VERSION "1.0"

NS_ :

BS_:

BU_: GENSET

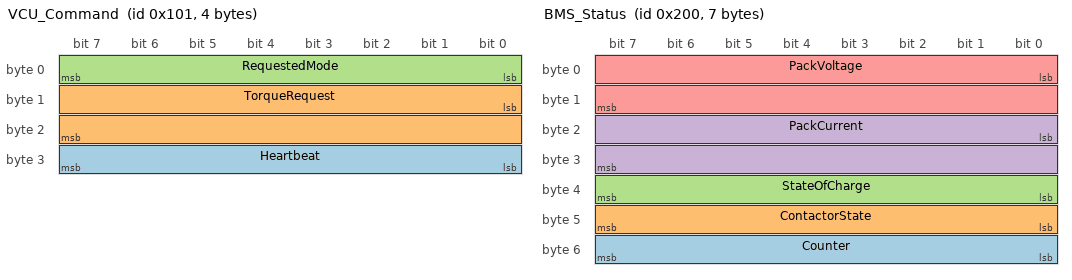
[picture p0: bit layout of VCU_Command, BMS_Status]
BO_ 257 VCU_Command: 4 VCU
 SG_ Heartbeat : 24|8@1+ (1,0) [0|255] ""  BMS,DCDC
 SG_ TorqueRequest : 8|16@1- (0.1,0) [-1000|1000] "Nm"  BMS,DCDC
 SG_ RequestedMode : 0|8@1+ (1,0) [0|3] ""  BMS,DCDC

BO_ 512 BMS_Status: 7 BMS
 SG_ Counter : 48|8@1+ (1,0) [0|255] ""  VCU,DCDC
 SG_ ContactorState : 40|8@1+ (1,0) [0|3] ""  VCU,DCDC
 SG_ StateOfCharge : 32|8@1+ (0.5,0) [0|100] "%"  VCU,DCDC
 SG_ PackCurrent : 16|16@1- (0.1,0) [-1000|1000] "A"  VCU,DCDC
 SG_ PackVoltage : 0|16@1+ (0.1,0) [0|1000] "V"  VCU,DCDC

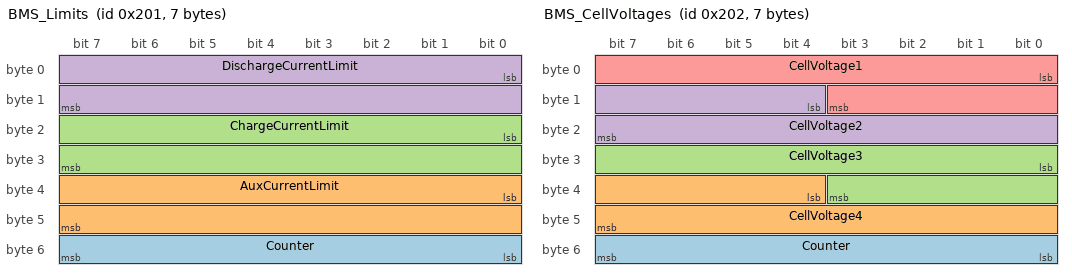
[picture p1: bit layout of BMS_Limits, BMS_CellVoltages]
BO_ 513 BMS_Limits: 7 BMS
 SG_ Counter : 48|8@1+ (1,0) [0|255] ""  VCU,DCDC
 SG_ AuxCurrentLimit : 32|16@1+ (0.01,0) [0|655.35] "A"  VCU,DCDC
 SG_ ChargeCurrentLimit : 16|16@1+ (0.01,0) [0|655.35] "A"  VCU,DCDC
 SG_ DischargeCurrentLimit : 0|16@1+ (0.01,0) [0|655.35] "A"  VCU,DCDC

BO_ 514 BMS_CellVoltages: 7 BMS
 SG_ Counter : 48|8@1+ (1,0) [0|255] ""  VCU
 SG_ CellVoltage4 : 36|12@1+ (0.001,2) [2|6.095] "V"  VCU
 SG_ CellVoltage3 : 24|12@1+ (0.001,2) [2|6.095] "V"  VCU
 SG_ CellVoltage2 : 12|12@1+ (0.001,2) [2|6.095] "V"  VCU
 SG_ CellVoltage1 : 0|12@1+ (0.001,2) [2|6.095] "V"  VCU

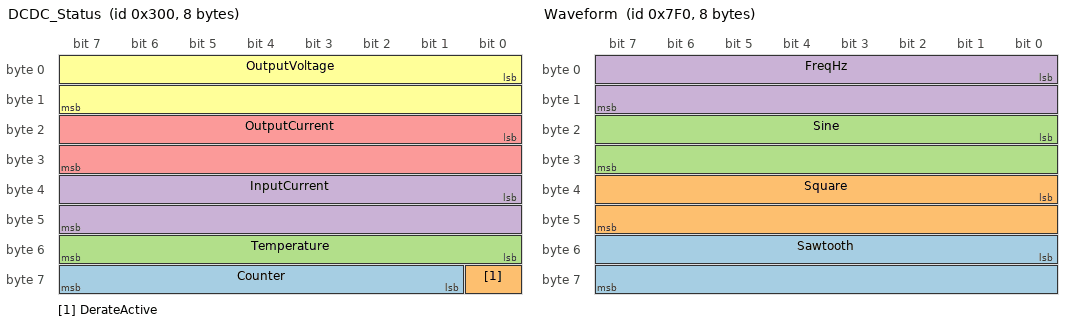
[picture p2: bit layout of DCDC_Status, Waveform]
BO_ 768 DCDC_Status: 8 DCDC
 SG_ Counter : 57|7@1+ (1,0) [0|127] ""  VCU,BMS
 SG_ DerateActive : 56|1@1+ (1,0) [0|1] ""  VCU,BMS
 SG_ Temperature : 48|8@1+ (1,-40) [-40|215] "degC"  VCU,BMS
 SG_ InputCurrent : 32|16@1+ (0.01,0) [0|655.35] "A"  VCU,BMS
 SG_ OutputCurrent : 16|16@1+ (0.1,0) [0|6553.5] "A"  VCU,BMS
 SG_ OutputVoltage : 0|16@1+ (0.01,0) [0|655.35] "V"  VCU,BMS

BO_ 2032 Waveform: 8 SIG
 SG_ Sawtooth : 48|16@1- (0.001,0) [-1|1] ""  VCU
 SG_ Square : 32|16@1- (0.001,0) [-1|1] ""  VCU
 SG_ Sine : 16|16@1- (0.001,0) [-1|1] ""  VCU
 SG_ FreqHz : 0|16@1+ (0.01,0) [0|655.35] "Hz"  VCU

BO_ 2364540032 EEC1: 8 GENSET
 SG_ EngineSpeed : 24|16@1+ (0.125,0) [0|8031.875] "rpm" Vector__XXX
 SG_ ActualEnginePercentTorque : 16|8@1+ (1,-125) [-125|125] "%" Vector__XXX

BO_ 2566844032 ET1: 8 GENSET
 SG_ EngineCoolantTemp : 0|8@1+ (1,-40) [-40|210] "degC" Vector__XXX

BO_ 2566838912 SOFT: 48 GENSET
 SG_ SoftwareIdByte47 : 376|8@1+ (1,0) [0|255] "" Vector__XXX
 SG_ SoftwareIdByte46 : 368|8@1+ (1,0) [0|255] "" Vector__XXX
 SG_ SoftwareIdByte45 : 360|8@1+ (1,0) [0|255] "" Vector__XXX
 SG_ SoftwareIdByte44 : 352|8@1+ (1,0) [0|255] "" Vector__XXX
 SG_ SoftwareIdByte43 : 344|8@1+ (1,0) [0|255] "" Vector__XXX
 SG_ SoftwareIdByte42 : 336|8@1+ (1,0) [0|255] "" Vector__XXX
 SG_ SoftwareIdByte41 : 328|8@1+ (1,0) [0|255] "" Vector__XXX
 SG_ SoftwareIdByte40 : 320|8@1+ (1,0) [0|255] "" Vector__XXX
 SG_ SoftwareIdByte39 : 312|8@1+ (1,0) [0|255] "" Vector__XXX
 SG_ SoftwareIdByte38 : 304|8@1+ (1,0) [0|255] "" Vector__XXX
 SG_ SoftwareIdByte37 : 296|8@1+ (1,0) [0|255] "" Vector__XXX
 SG_ SoftwareIdByte36 : 288|8@1+ (1,0) [0|255] "" Vector__XXX
 SG_ SoftwareIdByte35 : 280|8@1+ (1,0) [0|255] "" Vector__XXX
 SG_ SoftwareIdByte34 : 272|8@1+ (1,0) [0|255] "" Vector__XXX
 SG_ SoftwareIdByte33 : 264|8@1+ (1,0) [0|255] "" Vector__XXX
 SG_ SoftwareIdByte32 : 256|8@1+ (1,0) [0|255] "" Vector__XXX
 SG_ SoftwareIdByte31 : 248|8@1+ (1,0) [0|255] "" Vector__XXX
 SG_ SoftwareIdByte30 : 240|8@1+ (1,0) [0|255] "" Vector__XXX
 SG_ SoftwareIdByte29 : 232|8@1+ (1,0) [0|255] "" Vector__XXX
 SG_ SoftwareIdByte28 : 224|8@1+ (1,0) [0|255] "" Vector__XXX
 SG_ SoftwareIdByte27 : 216|8@1+ (1,0) [0|255] "" Vector__XXX
 SG_ SoftwareIdByte26 : 208|8@1+ (1,0) [0|255] "" Vector__XXX
 SG_ SoftwareIdByte25 : 200|8@1+ (1,0) [0|255] "" Vector__XXX
 SG_ SoftwareIdByte24 : 192|8@1+ (1,0) [0|255] "" Vector__XXX
 SG_ SoftwareIdByte23 : 184|8@1+ (1,0) [0|255] "" Vector__XXX
 SG_ SoftwareIdByte22 : 176|8@1+ (1,0) [0|255] "" Vector__XXX
 SG_ SoftwareIdByte21 : 168|8@1+ (1,0) [0|255] "" Vector__XXX
 SG_ SoftwareIdByte20 : 160|8@1+ (1,0) [0|255] "" Vector__XXX
 SG_ SoftwareIdByte19 : 152|8@1+ (1,0) [0|255] "" Vector__XXX
 SG_ SoftwareIdByte18 : 144|8@1+ (1,0) [0|255] "" Vector__XXX
 SG_ SoftwareIdByte17 : 136|8@1+ (1,0) [0|255] "" Vector__XXX
 SG_ SoftwareIdByte16 : 128|8@1+ (1,0) [0|255] "" Vector__XXX
 SG_ SoftwareIdByte15 : 120|8@1+ (1,0) [0|255] "" Vector__XXX
 SG_ SoftwareIdByte14 : 112|8@1+ (1,0) [0|255] "" Vector__XXX
 SG_ SoftwareIdByte13 : 104|8@1+ (1,0) [0|255] "" Vector__XXX
 SG_ SoftwareIdByte12 : 96|8@1+ (1,0) [0|255] "" Vector__XXX
 SG_ SoftwareIdByte11 : 88|8@1+ (1,0) [0|255] "" Vector__XXX
 SG_ SoftwareIdByte10 : 80|8@1+ (1,0) [0|255] "" Vector__XXX
 SG_ SoftwareIdByte09 : 72|8@1+ (1,0) [0|255] "" Vector__XXX
 SG_ SoftwareIdByte08 : 64|8@1+ (1,0) [0|255] "" Vector__XXX
 SG_ SoftwareIdByte07 : 56|8@1+ (1,0) [0|255] "" Vector__XXX
 SG_ SoftwareIdByte06 : 48|8@1+ (1,0) [0|255] "" Vector__XXX
 SG_ SoftwareIdByte05 : 40|8@1+ (1,0) [0|255] "" Vector__XXX
 SG_ SoftwareIdByte04 : 32|8@1+ (1,0) [0|255] "" Vector__XXX
 SG_ SoftwareIdByte03 : 24|8@1+ (1,0) [0|255] "" Vector__XXX
 SG_ SoftwareIdByte02 : 16|8@1+ (1,0) [0|255] "" Vector__XXX
 SG_ SoftwareIdByte01 : 8|8@1+ (1,0) [0|255] "" Vector__XXX
 SG_ NumberOfSoftwareIdFields : 0|8@1+ (1,0) [0|255] "" Vector__XXX

CM_ BU_ GENSET "Range extender engine ECU. J1939, preferred source address 0x80, arbitrary-address capable.";
CM_ BO_ 257 "Operating mode request and heartbeat. The BMS and DC-DC both follow the commanded mode.";
CM_ SG_ 257 TorqueRequest "Positive is drive, negative is regenerative braking.";
CM_ BO_ 512 "Pack-level measurements and contactor state.";
CM_ SG_ 512 PackCurrent "Positive is discharge, negative is charge.";
CM_ BO_ 513 "The current envelope the pack allows right now. AuxCurrentLimit bounds what the DC-DC may draw from the pack.";
CM_ SG_ 513 AuxCurrentLimit "Pack current the DC-DC converter may draw. The BMS reduces it while charging.";
CM_ SG_ 513 DischargeCurrentLimit "Pack-level ceiling for traction draw.";
CM_ BO_ 514 "Per-cell voltages. Four cells, one frame, no multiplexing.";
CM_ BO_ 768 "DC-DC converter state. InputCurrent is drawn from the pack and must stay within BMS_Limits.AuxCurrentLimit.";
CM_ SG_ 768 DerateActive "Set when the converter is limiting output because of temperature.";
CM_ SG_ 768 InputCurrent "Current drawn from the high-voltage pack.";
CM_ BO_ 2032 "Signal generator: one phase, chirped 1 to 100 Hz over 20 s, as sine, square and sawtooth. Lowest-priority ID on the bus.";
CM_ BO_ 2364540032 "Electronic Engine Controller 1, PGN 61444.";
CM_ BO_ 2566844032 "Engine Temperature 1, PGN 65262.";
CM_ BO_ 2566838912 "Software Identification, PGN 65242, on request only: RTS/CTS to a requester, BAM to a global request. The ASCII fields, each ending in '*', byte by byte.";
BA_DEF_  "ProtocolType" STRING ;
BA_DEF_ BO_  "VFrameFormat" ENUM  "StandardCAN","ExtendedCAN","reserved","J1939PG";
BA_DEF_ BO_  "GenMsgCycleTime" INT 0 10000;
BA_DEF_ SG_  "SPN" INT 0 524287;
BA_DEF_DEF_  "ProtocolType" "";
BA_DEF_DEF_  "VFrameFormat" "J1939PG";
BA_DEF_DEF_  "GenMsgCycleTime" 0;
BA_DEF_DEF_  "SPN" 0;
BA_ "ProtocolType" "J1939";
BA_ "GenMsgCycleTime" BO_ 257 100;
BA_ "VFrameFormat" BO_ 257 0;
BA_ "GenMsgCycleTime" BO_ 512 100;
BA_ "VFrameFormat" BO_ 512 0;
BA_ "GenMsgCycleTime" BO_ 513 100;
BA_ "VFrameFormat" BO_ 513 0;
BA_ "GenMsgCycleTime" BO_ 514 500;
BA_ "VFrameFormat" BO_ 514 0;
BA_ "GenMsgCycleTime" BO_ 768 50;
BA_ "VFrameFormat" BO_ 768 0;
BA_ "GenMsgCycleTime" BO_ 2032 2;
BA_ "VFrameFormat" BO_ 2032 0;
BA_ "GenMsgCycleTime" BO_ 2364540032 100;
BA_ "SPN" SG_ 2364540032 EngineSpeed 190;
BA_ "SPN" SG_ 2364540032 ActualEnginePercentTorque 513;
BA_ "GenMsgCycleTime" BO_ 2566844032 1000;
BA_ "SPN" SG_ 2566844032 EngineCoolantTemp 110;
BA_ "SPN" SG_ 2566838912 NumberOfSoftwareIdFields 965;
VAL_ 257 RequestedMode 0 "Standby" 1 "Drive" 2 "Charge" 3 "Fault" ;
VAL_ 512 ContactorState 0 "Open" 1 "Precharge" 2 "Closed" 3 "Fault" ;
VAL_ 768 DerateActive 0 "Inactive" 1 "Active" ;
